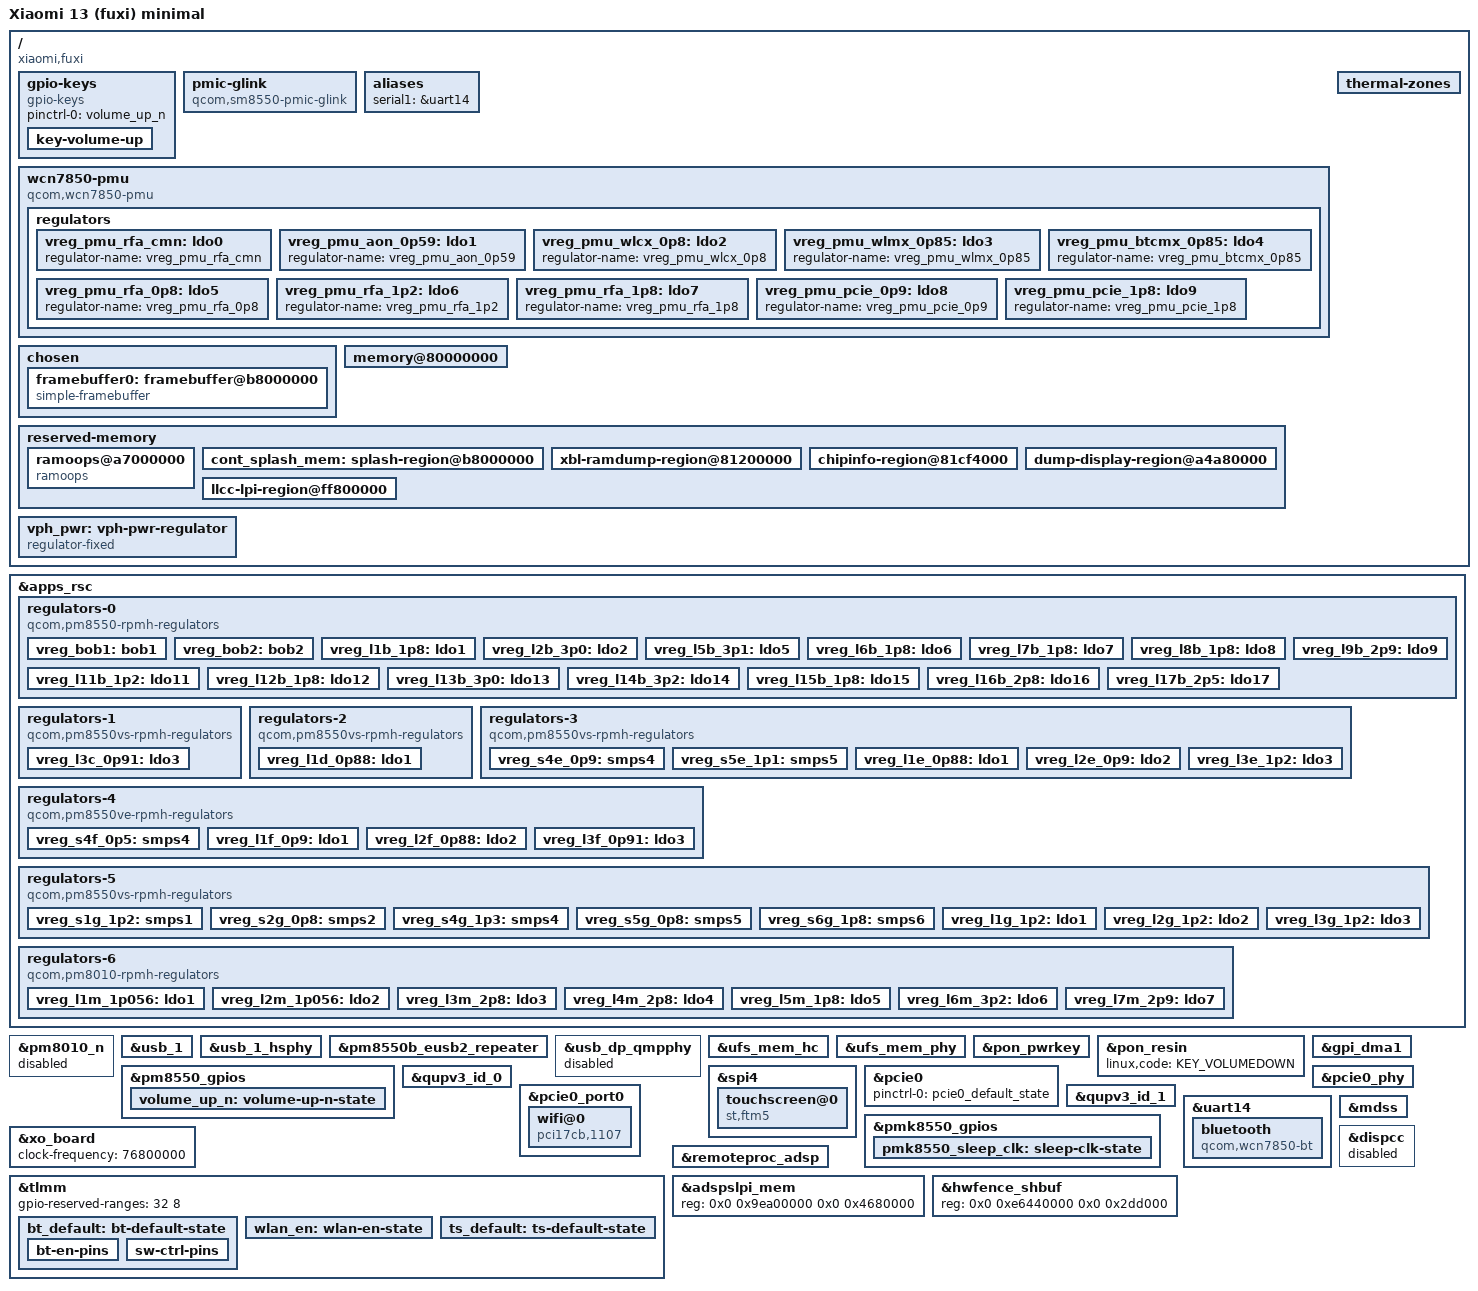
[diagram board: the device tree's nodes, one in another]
// SPDX-License-Identifier: BSD-3-Clause
/*
 * Xiaomi 13 (fuxi) 最小主线板级 DTS —— 只为“内核能启动 + USB 串口工作”
 * 生成方式：从 sm8550-mtp.dts 裁剪（保留 PMIC 调压器与 USB 子树）
 */

/dts-v1/;

#include <dt-bindings/regulator/qcom,rpmh-regulator.h>
#include "sm8550.dtsi"
#include "pm8010.dtsi"
#include "pm8550.dtsi"
#include "pm8550b.dtsi"
#define PMK8550VE_SID 5
#include "pm8550ve.dtsi"
#include "pm8550vs.dtsi"
#include "pmk8550.dtsi"
#include "pmr735d_a.dtsi"


/ {
	model = "Xiaomi 13 (fuxi) minimal";
	compatible = "xiaomi,fuxi", "qcom,sm8550";
	chassis-type = "handset";

	/* ABL 按这两项从 boot 镜像里挑 DTB（值取自厂商 fuxi DTB）；没有它们 ABL 报 Load Error */
	qcom,msm-id = <519 0x20000>, <536 0x20000>;
	qcom,board-id = <0x10008 0>;

	/* 音量上：PM8550 GPIO6，低有效（厂商 DTB gpio_keys/vol_up；与 sm8550-qrd 相同） */
	gpio-keys {
		compatible = "gpio-keys";

		pinctrl-0 = <&volume_up_n>;
		pinctrl-names = "default";

		key-volume-up {
			label = "Volume Up";
			linux,code = <KEY_VOLUMEUP>;
			gpios = <&pm8550_gpios 6 GPIO_ACTIVE_LOW>;
			debounce-interval = <15>;
			linux,can-disable;
			wakeup-source;
		};
	};

	/*
	 * 电池/充电：ADSP 上的 battmgr 经 pmic_glink 暴露电量与充电状态。
	 * 暂不接 USB-C connector（不编 UCSI），USB 保持固定 peripheral，免得 ADSP 切换角色断开 USB 网络。
	 */
	pmic-glink {
		compatible = "qcom,sm8550-pmic-glink", "qcom,pmic-glink";
		#address-cells = <1>;
		#size-cells = <0>;
	};

	aliases {
		serial1 = &uart14;
	};

	/*
	 * WiFi/蓝牙：WCN7850（Kiwi）。引脚与 sm8550-qrd 完全相同（厂商 DTB cnss/bt_kiwi：
	 * wlan-en GPIO80、bt-en GPIO81、sw-ctrl GPIO82；PCIe0 perst GPIO94、wake GPIO96），
	 * 供电对应关系同 QRD（只是 fuxi DTS 里的标签名不同）。
	 */
	wcn7850-pmu {
		compatible = "qcom,wcn7850-pmu";

		pinctrl-0 = <&wlan_en>, <&bt_default>, <&pmk8550_sleep_clk>;
		pinctrl-names = "default";

		wlan-enable-gpios = <&tlmm 80 GPIO_ACTIVE_HIGH>;
		bt-enable-gpios = <&tlmm 81 GPIO_ACTIVE_HIGH>;

		vdd-supply = <&vreg_s5g_0p8>;
		vddio-supply = <&vreg_l15b_1p8>;
		vddaon-supply = <&vreg_s2g_0p8>;
		vdddig-supply = <&vreg_s4e_0p9>;
		vddrfa1p2-supply = <&vreg_s4g_1p3>;
		vddrfa1p8-supply = <&vreg_s6g_1p8>;

		regulators {
			vreg_pmu_rfa_cmn: ldo0 {
				regulator-name = "vreg_pmu_rfa_cmn";
			};

			vreg_pmu_aon_0p59: ldo1 {
				regulator-name = "vreg_pmu_aon_0p59";
			};

			vreg_pmu_wlcx_0p8: ldo2 {
				regulator-name = "vreg_pmu_wlcx_0p8";
			};

			vreg_pmu_wlmx_0p85: ldo3 {
				regulator-name = "vreg_pmu_wlmx_0p85";
			};

			vreg_pmu_btcmx_0p85: ldo4 {
				regulator-name = "vreg_pmu_btcmx_0p85";
			};

			vreg_pmu_rfa_0p8: ldo5 {
				regulator-name = "vreg_pmu_rfa_0p8";
			};

			vreg_pmu_rfa_1p2: ldo6 {
				regulator-name = "vreg_pmu_rfa_1p2";
			};

			vreg_pmu_rfa_1p8: ldo7 {
				regulator-name = "vreg_pmu_rfa_1p8";
			};

			vreg_pmu_pcie_0p9: ldo8 {
				regulator-name = "vreg_pmu_pcie_0p9";
			};

			vreg_pmu_pcie_1p8: ldo9 {
				regulator-name = "vreg_pmu_pcie_1p8";
			};
		};
	};

	chosen {
		#address-cells = <2>;
		#size-cells = <2>;
		ranges;

		/*
		 * 内核 cmdline 的唯一来源（ABL 启动时内核用内建 DTB，ABL 传的 cmdline 不生效）。
		 * 末尾的空格是给旧的 UEFI 跳板（FuxiLinuxBoot 原地改写）留的余量。
		 * 不要加 console=ttyGS0：/dev/console 会变成 USB 串口，主机没打开串口时缓冲区写满，
		 * 往 /dev/console 写的进程（systemd 状态输出）全部阻塞——启动卡 6 分钟、关机永远卡住。
		 */
		bootargs = "loglevel=7 log_buf_len=2M panic=0 clk_ignore_unused pd_ignore_unused regulator_ignore_unused arm-smmu.disable_bypass=0 cpuidle.off=1 fbcon=font:TER16x32 console=tty0 fuxi.fb=0xB8000000,1080,2400,1080,32 rdinit=/init g_cdc.idVendor=0x0525 g_cdc.idProduct=0xa4a7 g_cdc.dev_addr=02:f0:c5:13:00:02 g_cdc.host_addr=02:f0:c5:13:00:01                                                                                                                                                                                                                                                                                                                                                                                                                                                                                                                                                                                                                                                                                                                                                                                                                                ";

		/*
		 * bootloader（ABL/UEFI）留下的帧缓冲：1080x2400 XRGB8888，stride 4320。
		 * 面板是 DSI command mode，MDSS autorefresh 持续从这里取帧；simpledrm 接管它
		 * 当作标准显示设备（/dev/dri/card0 + fbcon）。内存在 reserved-memory 里保留。
		 */
		framebuffer0: framebuffer@b8000000 {
			compatible = "simple-framebuffer";
			reg = <0x0 0xb8000000 0x0 0x9e3400>;
			width = <1080>;
			height = <2400>;
			stride = <(1080 * 4)>;
			format = "x8r8g8b8";
		};
	};

	/*
	 * 内存与固件保留区按"运行中系统"的 DTB（/sys/firmware/fdt，ABL 按本机 DDR 改写过，
	 * 存档 work/device-info/fuxi-live.dts）：这台是 12 GB 版本。之前这里的布局来自不匹配的
	 * 厂商 DTB：少了 4 GB，还把 0x8b9d00000 等几段非内存/受保护区声明成了内存。
	 * 内建 DTB 忽略 ABL 的改写，所以这份布局只对这台机器有效。
	 */
	memory@80000000 {
		device_type = "memory";
		reg = <0x0 0x80000000 0x0 0x00e00000>,
		      <0x0 0x811d0000 0x0 0x56e30000>,
		      <0x0 0xd8140000 0x0 0x00020000>,
		      <0x0 0xe7cb0000 0x0 0x18350000>,
		      <0x8 0x80000000 0x0 0x39d00000>,
		      <0x8 0xb9f00000 0x0 0x01e00000>,
		      <0x8 0xc0000000 0x0 0xc0000000>,
		      <0x9 0x80000000 0x1 0x80000000>;
	};

	/*
	 * 固件保留区以 sm8550.dtsi 为准（与本机固件布局一致），只补运行中 DTB 里多出来的几段，
	 * 尺寸不同的在文件末尾按标签改。
	 */
	reserved-memory {
		#address-cells = <2>;
		#size-cells = <2>;
		ranges;

		/*
		 * 厂商 DTB 的 ramoops@0xa7000000：热重启后保留上一轮的内核日志（/sys/fs/pstore），
		 * 用来查卡死/重启原因。4 MB = 2 MB console + 2 MB pmsg，与 Android 一致。
		 */
		ramoops@a7000000 {
			compatible = "ramoops";
			reg = <0x0 0xa7000000 0x0 0x400000>;
			console-size = <0x200000>;
			pmsg-size = <0x200000>;
		};

		/* 厂商 DTB 的 cont_splash_region：bootloader 帧缓冲，不能给内核当普通内存用 */
		cont_splash_mem: splash-region@b8000000 {
			reg = <0x0 0xb8000000 0x0 0x2b00000>;
			no-map;
		};

		xbl-ramdump-region@81200000 {
			reg = <0x0 0x81200000 0x0 0x280000>;
			no-map;
		};

		chipinfo-region@81cf4000 {
			reg = <0x0 0x81cf4000 0x0 0x1000>;
			no-map;
		};

		dump-display-region@a4a80000 {
			reg = <0x0 0xa4a80000 0x0 0x800>;
			no-map;
		};

		llcc-lpi-region@ff800000 {
			reg = <0x0 0xff800000 0x0 0x600000>;
			no-map;
		};
	};

	vph_pwr: vph-pwr-regulator {
		compatible = "regulator-fixed";
		regulator-name = "vph_pwr";
		regulator-min-microvolt = <3700000>;
		regulator-max-microvolt = <3700000>;
		regulator-always-on;
		regulator-boot-on;
	};
};

&apps_rsc {
	regulators-0 {
		compatible = "qcom,pm8550-rpmh-regulators";
		qcom,pmic-id = "b";

		vdd-bob1-supply = <&vph_pwr>;
		vdd-bob2-supply = <&vph_pwr>;
		vdd-l1-l4-l10-supply = <&vreg_s6g_1p8>;
		vdd-l2-l13-l14-supply = <&vreg_bob1>;
		vdd-l3-supply = <&vreg_s4g_1p3>;
		vdd-l5-l16-supply = <&vreg_bob1>;
		vdd-l6-l7-supply = <&vreg_bob1>;
		vdd-l8-l9-supply = <&vreg_bob1>;
		vdd-l11-supply = <&vreg_s4g_1p3>;
		vdd-l12-supply = <&vreg_s6g_1p8>;
		vdd-l15-supply = <&vreg_s6g_1p8>;
		vdd-l17-supply = <&vreg_bob2>;

		vreg_bob1: bob1 {
			regulator-name = "vreg_bob1";
			regulator-min-microvolt = <3296000>;
			regulator-max-microvolt = <3960000>;
			regulator-initial-mode = <RPMH_REGULATOR_MODE_HPM>;
		};

		vreg_bob2: bob2 {
			regulator-name = "vreg_bob2";
			regulator-min-microvolt = <2720000>;
			regulator-max-microvolt = <3960000>;
			regulator-initial-mode = <RPMH_REGULATOR_MODE_HPM>;
		};

		vreg_l1b_1p8: ldo1 {
			regulator-name = "vreg_l1b_1p8";
			regulator-min-microvolt = <1800000>;
			regulator-max-microvolt = <1800000>;
			regulator-initial-mode = <RPMH_REGULATOR_MODE_HPM>;
		};

		vreg_l2b_3p0: ldo2 {
			regulator-name = "vreg_l2b_3p0";
			regulator-min-microvolt = <3008000>;
			regulator-max-microvolt = <3008000>;
			regulator-initial-mode = <RPMH_REGULATOR_MODE_HPM>;
		};

		vreg_l5b_3p1: ldo5 {
			regulator-name = "vreg_l5b_3p1";
			regulator-min-microvolt = <3104000>;
			regulator-max-microvolt = <3104000>;
			regulator-initial-mode = <RPMH_REGULATOR_MODE_HPM>;
		};

		vreg_l6b_1p8: ldo6 {
			regulator-name = "vreg_l6b_1p8";
			regulator-min-microvolt = <1800000>;
			regulator-max-microvolt = <3008000>;
			regulator-initial-mode = <RPMH_REGULATOR_MODE_HPM>;
		};

		vreg_l7b_1p8: ldo7 {
			regulator-name = "vreg_l7b_1p8";
			regulator-min-microvolt = <1800000>;
			regulator-max-microvolt = <3008000>;
			regulator-initial-mode = <RPMH_REGULATOR_MODE_HPM>;
		};

		vreg_l8b_1p8: ldo8 {
			regulator-name = "vreg_l8b_1p8";
			regulator-min-microvolt = <1800000>;
			regulator-max-microvolt = <3008000>;
			regulator-initial-mode = <RPMH_REGULATOR_MODE_HPM>;
		};

		vreg_l9b_2p9: ldo9 {
			regulator-name = "vreg_l9b_2p9";
			regulator-min-microvolt = <2960000>;
			regulator-max-microvolt = <3008000>;
			regulator-initial-mode = <RPMH_REGULATOR_MODE_HPM>;
		};

		vreg_l11b_1p2: ldo11 {
			regulator-name = "vreg_l11b_1p2";
			regulator-min-microvolt = <1200000>;
			regulator-max-microvolt = <1504000>;
			regulator-initial-mode = <RPMH_REGULATOR_MODE_HPM>;
		};

		vreg_l12b_1p8: ldo12 {
			regulator-name = "vreg_l12b_1p8";
			regulator-min-microvolt = <1800000>;
			regulator-max-microvolt = <1800000>;
			regulator-initial-mode = <RPMH_REGULATOR_MODE_HPM>;
		};

		vreg_l13b_3p0: ldo13 {
			regulator-name = "vreg_l13b_3p0";
			regulator-min-microvolt = <3000000>;
			regulator-max-microvolt = <3000000>;
			regulator-initial-mode = <RPMH_REGULATOR_MODE_HPM>;
		};

		vreg_l14b_3p2: ldo14 {
			regulator-name = "vreg_l14b_3p2";
			regulator-min-microvolt = <3200000>;
			regulator-max-microvolt = <3200000>;
			regulator-initial-mode = <RPMH_REGULATOR_MODE_HPM>;
		};

		vreg_l15b_1p8: ldo15 {
			regulator-name = "vreg_l15b_1p8";
			regulator-min-microvolt = <1800000>;
			regulator-max-microvolt = <1800000>;
			regulator-initial-mode = <RPMH_REGULATOR_MODE_HPM>;
		};

		vreg_l16b_2p8: ldo16 {
			regulator-name = "vreg_l16b_2p8";
			regulator-min-microvolt = <2800000>;
			regulator-max-microvolt = <2800000>;
			regulator-initial-mode = <RPMH_REGULATOR_MODE_HPM>;
		};

		vreg_l17b_2p5: ldo17 {
			regulator-name = "vreg_l17b_2p5";
			regulator-min-microvolt = <2504000>;
			regulator-max-microvolt = <2504000>;
			regulator-initial-mode = <RPMH_REGULATOR_MODE_HPM>;
		};
	};

	regulators-1 {
		compatible = "qcom,pm8550vs-rpmh-regulators";
		qcom,pmic-id = "c";

		vdd-l3-supply = <&vreg_s4e_0p9>;

		vreg_l3c_0p91: ldo3 {
			regulator-name = "vreg_l3c_0p9";
			regulator-min-microvolt = <880000>;
			regulator-max-microvolt = <912000>;
			regulator-initial-mode = <RPMH_REGULATOR_MODE_HPM>;
		};
	};

	regulators-2 {
		compatible = "qcom,pm8550vs-rpmh-regulators";
		qcom,pmic-id = "d";

		vdd-l1-supply = <&vreg_s4e_0p9>;

		vreg_l1d_0p88: ldo1 {
			regulator-name = "vreg_l1d_0p88";
			regulator-min-microvolt = <880000>;
			regulator-max-microvolt = <920000>;
			regulator-initial-mode = <RPMH_REGULATOR_MODE_HPM>;
		};
	};

	regulators-3 {
		compatible = "qcom,pm8550vs-rpmh-regulators";
		qcom,pmic-id = "e";

		vdd-l1-supply = <&vreg_s4e_0p9>;
		vdd-l2-supply = <&vreg_s4e_0p9>;
		vdd-l3-supply = <&vreg_s4g_1p3>;
		vdd-s4-supply = <&vph_pwr>;
		vdd-s5-supply = <&vph_pwr>;

		vreg_s4e_0p9: smps4 {
			regulator-name = "vreg_s4e_0p9";
			regulator-min-microvolt = <904000>;
			regulator-max-microvolt = <984000>;
			regulator-initial-mode = <RPMH_REGULATOR_MODE_HPM>;
		};

		vreg_s5e_1p1: smps5 {
			regulator-name = "vreg_s5e_1p1";
			regulator-min-microvolt = <1080000>;
			regulator-max-microvolt = <1120000>;
			regulator-initial-mode = <RPMH_REGULATOR_MODE_HPM>;
		};

		vreg_l1e_0p88: ldo1 {
			regulator-name = "vreg_l1e_0p88";
			regulator-min-microvolt = <880000>;
			regulator-max-microvolt = <880000>;
			regulator-initial-mode = <RPMH_REGULATOR_MODE_HPM>;
		};

		vreg_l2e_0p9: ldo2 {
			regulator-name = "vreg_l2e_0p9";
			regulator-min-microvolt = <904000>;
			regulator-max-microvolt = <970000>;
			regulator-initial-mode = <RPMH_REGULATOR_MODE_HPM>;
		};

		vreg_l3e_1p2: ldo3 {
			regulator-name = "vreg_l3e_1p2";
			regulator-min-microvolt = <1200000>;
			regulator-max-microvolt = <1200000>;
			regulator-initial-mode = <RPMH_REGULATOR_MODE_HPM>;
		};
	};

	regulators-4 {
		compatible = "qcom,pm8550ve-rpmh-regulators";
		qcom,pmic-id = "f";

		vdd-l1-supply = <&vreg_s4e_0p9>;
		vdd-l2-supply = <&vreg_s4e_0p9>;
		vdd-l3-supply = <&vreg_s4e_0p9>;
		vdd-s4-supply = <&vph_pwr>;

		vreg_s4f_0p5: smps4 {
			regulator-name = "vreg_s4f_0p5";
			regulator-min-microvolt = <500000>;
			regulator-max-microvolt = <700000>;
			regulator-initial-mode = <RPMH_REGULATOR_MODE_HPM>;
		};

		vreg_l1f_0p9: ldo1 {
			regulator-name = "vreg_l1f_0p9";
			regulator-min-microvolt = <912000>;
			regulator-max-microvolt = <912000>;
			regulator-initial-mode = <RPMH_REGULATOR_MODE_HPM>;
		};

		vreg_l2f_0p88: ldo2 {
			regulator-name = "vreg_l2f_0p88";
			regulator-min-microvolt = <880000>;
			regulator-max-microvolt = <912000>;
			regulator-initial-mode = <RPMH_REGULATOR_MODE_HPM>;
		};

		vreg_l3f_0p91: ldo3 {
			regulator-name = "vreg_l3f_0p91";
			regulator-min-microvolt = <880000>;
			regulator-max-microvolt = <912000>;
			regulator-initial-mode = <RPMH_REGULATOR_MODE_HPM>;
		};
	};

	regulators-5 {
		compatible = "qcom,pm8550vs-rpmh-regulators";
		qcom,pmic-id = "g";

		vdd-l1-supply = <&vreg_s4g_1p3>;
		vdd-l2-supply = <&vreg_s4g_1p3>;
		vdd-l3-supply = <&vreg_s4g_1p3>;
		vdd-s1-supply = <&vph_pwr>;
		vdd-s2-supply = <&vph_pwr>;
		vdd-s3-supply = <&vph_pwr>;
		vdd-s4-supply = <&vph_pwr>;
		vdd-s5-supply = <&vph_pwr>;
		vdd-s6-supply = <&vph_pwr>;

		vreg_s1g_1p2: smps1 {
			regulator-name = "vreg_s1g_1p2";
			regulator-min-microvolt = <1200000>;
			regulator-max-microvolt = <1300000>;
			regulator-initial-mode = <RPMH_REGULATOR_MODE_HPM>;
		};

		vreg_s2g_0p8: smps2 {
			regulator-name = "vreg_s2g_0p8";
			regulator-min-microvolt = <800000>;
			regulator-max-microvolt = <1000000>;
			regulator-initial-mode = <RPMH_REGULATOR_MODE_HPM>;
		};

		/*
		 * fuxi 的 cmd-db 没有 smpg3（work/device-info/cmd-db-fuxi.txt），
		 * 保留 MTP 的 smps3 会让整块 regulators-5 以 -ENODEV 静默失败。
		 */

		vreg_s4g_1p3: smps4 {
			regulator-name = "vreg_s4g_1p3";
			regulator-min-microvolt = <1200000>;
			regulator-max-microvolt = <1352000>;
			regulator-initial-mode = <RPMH_REGULATOR_MODE_HPM>;
		};

		vreg_s5g_0p8: smps5 {
			regulator-name = "vreg_s5g_0p8";
			regulator-min-microvolt = <500000>;
			regulator-max-microvolt = <1004000>;
			regulator-initial-mode = <RPMH_REGULATOR_MODE_HPM>;
		};

		vreg_s6g_1p8: smps6 {
			regulator-name = "vreg_s6g_1p8";
			regulator-min-microvolt = <1800000>;
			regulator-max-microvolt = <2000000>;
			regulator-initial-mode = <RPMH_REGULATOR_MODE_HPM>;
		};

		vreg_l1g_1p2: ldo1 {
			regulator-name = "vreg_l1g_1p2";
			regulator-min-microvolt = <1200000>;
			regulator-max-microvolt = <1200000>;
			regulator-initial-mode = <RPMH_REGULATOR_MODE_HPM>;
		};

		vreg_l2g_1p2: ldo2 {
			regulator-name = "vreg_l2g_1p2";
			regulator-min-microvolt = <1200000>;
			regulator-max-microvolt = <1200000>;
			regulator-initial-mode = <RPMH_REGULATOR_MODE_HPM>;
		};

		vreg_l3g_1p2: ldo3 {
			regulator-name = "vreg_l3g_1p2";
			regulator-min-microvolt = <1200000>;
			regulator-max-microvolt = <1200000>;
			regulator-initial-mode = <RPMH_REGULATOR_MODE_HPM>;
		};
	};

	regulators-6 {
		compatible = "qcom,pm8010-rpmh-regulators";
		qcom,pmic-id = "m";

		vdd-l1-l2-supply = <&vreg_s4g_1p3>;
		vdd-l3-l4-supply = <&vreg_bob2>;
		vdd-l5-supply = <&vreg_s6g_1p8>;
		vdd-l6-supply = <&vreg_s6g_1p8>;
		vdd-l7-supply = <&vreg_bob1>;

		vreg_l1m_1p056: ldo1 {
			regulator-name = "vreg_l1m_1p056";
			regulator-min-microvolt = <1056000>;
			regulator-max-microvolt = <1056000>;
			regulator-initial-mode = <RPMH_REGULATOR_MODE_HPM>;
		};

		vreg_l2m_1p056: ldo2 {
			regulator-name = "vreg_l2m_1p056";
			regulator-min-microvolt = <1056000>;
			regulator-max-microvolt = <1056000>;
			regulator-initial-mode = <RPMH_REGULATOR_MODE_HPM>;
		};

		vreg_l3m_2p8: ldo3 {
			regulator-name = "vreg_l3m_2p8";
			regulator-min-microvolt = <2800000>;
			regulator-max-microvolt = <2800000>;
			regulator-initial-mode = <RPMH_REGULATOR_MODE_HPM>;
		};

		vreg_l4m_2p8: ldo4 {
			regulator-name = "vreg_l4m_2p8";
			regulator-min-microvolt = <2800000>;
			regulator-max-microvolt = <2800000>;
			regulator-initial-mode = <RPMH_REGULATOR_MODE_HPM>;
		};

		vreg_l5m_1p8: ldo5 {
			regulator-name = "vreg_l5m_1p8";
			regulator-min-microvolt = <1800000>;
			regulator-max-microvolt = <1800000>;
			regulator-initial-mode = <RPMH_REGULATOR_MODE_HPM>;
		};

		/* 只给触摸屏 avdd 用；厂商 pm8010m_l6 默认 3.2V（范围 1.8–3.2V） */
		vreg_l6m_3p2: ldo6 {
			regulator-name = "vreg_l6m_3p2";
			regulator-min-microvolt = <3200000>;
			regulator-max-microvolt = <3200000>;
			regulator-initial-mode = <RPMH_REGULATOR_MODE_HPM>;
		};

		vreg_l7m_2p9: ldo7 {
			regulator-name = "vreg_l7m_2p9";
			regulator-min-microvolt = <2800000>;
			regulator-max-microvolt = <2904000>;
			regulator-initial-mode = <RPMH_REGULATOR_MODE_HPM>;
		};
	};

	/* PMIC "n"（第二颗 PM8010）在 fuxi 的 cmd-db 里没有任何资源：去掉 regulators-7 */
};

/*
 * fuxi 只有一颗 PM8010（USID 0xc）、一颗 PMR735D（0xa）：0xb/0xd 不存在（cmd-db 里也没有
 * PMIC "n" 的资源），probe 会报 spmi 通道错误并打调用栈。pmr735d_b.dtsi 不包含；pm8010.dtsi
 * 里的第二颗关掉，连同它的温度区。
 */
&pm8010_n {
	status = "disabled";
};

/ {
	thermal-zones {
		/delete-node/ pm8010-n-thermal;
	};
};

/* ===== USB：只要 gadget 串口能用（仅 USB2/eUSB2，不碰 USB3/DP combo PHY）===== */
&usb_1 {
	dr_mode = "peripheral";
	/delete-property/ usb-role-switch;
	phys = <&usb_1_hsphy>;
	phy-names = "usb2-phy";
	maximum-speed = "high-speed";
	/* 没有 SS PHY 提供 pipe clock，改用 UTMI 时钟 */
	qcom,select-utmi-as-pipe-clk;
	status = "okay";
};

&usb_1_hsphy {
	vdd-supply = <&vreg_l1e_0p88>;
	vdda12-supply = <&vreg_l3e_1p2>;

	phys = <&pm8550b_eusb2_repeater>;

	status = "okay";
};

/* repeater 在 PM8550B 上（SPMI 总线），供电同 sm8550-qrd */
&pm8550b_eusb2_repeater {
	vdd18-supply = <&vreg_l15b_1p8>;
	vdd3-supply = <&vreg_l5b_3p1>;
};

&usb_dp_qmpphy {
	vdda-phy-supply = <&vreg_l3f_0p91>;
	vdda-pll-supply = <&vreg_l3e_1p2>;

	status = "disabled";
};

/*
 * ===== UFS（M3）=====
 * 与 Android 实时 DTB（work/device-info/fuxi-live.dts，ufshc@1d84000）逐项核对过：
 * vcc=pm_humu_l17(l17b 2.504V)/1.3A、vccq=pm_v6g_l1(l1g)/1.2A、reset GPIO 210；
 * PHY vdda-phy=l1d、vdda-pll=l3e。与 sm8550-mtp 相同。
 */
&ufs_mem_hc {
	reset-gpios = <&tlmm 210 GPIO_ACTIVE_LOW>;
	vcc-supply = <&vreg_l17b_2p5>;
	vcc-max-microamp = <1300000>;
	vccq-supply = <&vreg_l1g_1p2>;
	vccq-max-microamp = <1200000>;
	vdd-hba-supply = <&vreg_l3g_1p2>;

	status = "okay";
};

&ufs_mem_phy {
	vdda-phy-supply = <&vreg_l1d_0p88>;
	vdda-pll-supply = <&vreg_l3e_1p2>;

	status = "okay";
};

/* 电源键与音量下（PMK8550 PON 的 resin），同 sm8550-qrd */
&pon_pwrkey {
	status = "okay";
};

&pon_resin {
	linux,code = <KEY_VOLUMEDOWN>;

	status = "okay";
};

&pm8550_gpios {
	volume_up_n: volume-up-n-state {
		pins = "gpio6";
		function = "normal";
		power-source = <1>;
		bias-pull-up;
		input-enable;
	};
};

/*
 * 触摸屏：ST FTM5（SPI，QUP0 SE4 = spi4，GPIO44-47），驱动 drivers/input/touchscreen/st-ftm5.c。
 * 取自厂商 DTB spi@a90000/fts@0："st,spi"、12 MHz、irq GPIO25 低电平、reset GPIO24（拉低复位）、
 * vdd = l12b（pm_humu_l12）、avdd = l6m（pm8010m_l6）。坐标是 1/10 像素（1080x2400 屏）。
 */
&gpi_dma1 {
	status = "okay";
};

&qupv3_id_0 {
	status = "okay";
};

&spi4 {
	status = "okay";

	touchscreen@0 {
		compatible = "st,ftm5";
		reg = <0>;
		spi-max-frequency = <12000000>;

		interrupts-extended = <&tlmm 25 IRQ_TYPE_LEVEL_LOW>;
		reset-gpios = <&tlmm 24 GPIO_ACTIVE_LOW>;

		vdd-supply = <&vreg_l12b_1p8>;
		avdd-supply = <&vreg_l6m_3p2>;

		pinctrl-0 = <&ts_default>;
		pinctrl-names = "default";

		touchscreen-size-x = <10800>;
		touchscreen-size-y = <24000>;
	};
};

&pcie0 {
	pinctrl-0 = <&pcie0_default_state>;
	pinctrl-names = "default";

	status = "okay";
};

&pcie0_phy {
	vdda-phy-supply = <&vreg_l1e_0p88>;
	vdda-pll-supply = <&vreg_l3e_1p2>;

	status = "okay";
};

&pcie0_port0 {
	reset-gpios = <&tlmm 94 GPIO_ACTIVE_LOW>;
	wake-gpios = <&tlmm 96 GPIO_ACTIVE_LOW>;

	wifi@0 {
		compatible = "pci17cb,1107";
		reg = <0x10000 0x0 0x0 0x0 0x0>;

		vddrfacmn-supply = <&vreg_pmu_rfa_cmn>;
		vddaon-supply = <&vreg_pmu_aon_0p59>;
		vddwlcx-supply = <&vreg_pmu_wlcx_0p8>;
		vddwlmx-supply = <&vreg_pmu_wlmx_0p85>;
		vddrfa0p8-supply = <&vreg_pmu_rfa_0p8>;
		vddrfa1p2-supply = <&vreg_pmu_rfa_1p2>;
		vddrfa1p8-supply = <&vreg_pmu_rfa_1p8>;
		vddpcie0p9-supply = <&vreg_pmu_pcie_0p9>;
		vddpcie1p8-supply = <&vreg_pmu_pcie_1p8>;
	};
};

/* QUP2（0x8c0000，主线叫 qupv3_id_1）：uart14 蓝牙、i2c8 扬声器功放都在它下面 */
&qupv3_id_1 {
	status = "okay";
};

&uart14 {
	status = "okay";

	bluetooth {
		compatible = "qcom,wcn7850-bt";

		vddrfacmn-supply = <&vreg_pmu_rfa_cmn>;
		vddaon-supply = <&vreg_pmu_aon_0p59>;
		vddwlcx-supply = <&vreg_pmu_wlcx_0p8>;
		vddwlmx-supply = <&vreg_pmu_wlmx_0p85>;
		vddrfa0p8-supply = <&vreg_pmu_rfa_0p8>;
		vddrfa1p2-supply = <&vreg_pmu_rfa_1p2>;
		vddrfa1p8-supply = <&vreg_pmu_rfa_1p8>;

		max-speed = <3200000>;
	};
};

&pmk8550_gpios {
	pmk8550_sleep_clk: sleep-clk-state {
		pins = "gpio3";
		function = "func1";
		input-disable;
		output-enable;
		bias-disable;
		power-source = <0>;
	};
};

&xo_board {
	clock-frequency = <76800000>;
};

/*
 * GPIO 32-39 归 TrustZone（厂商 kalama DTB: qcom,gpios-reserved = <32..39>）。
 * 缺这一行时 TLMM probe 读这些引脚的寄存器触发 XPU 违规：黑屏 + 整机卡死 + 看门狗复位。
 */
&tlmm {
	gpio-reserved-ranges = <32 8>;

	bt_default: bt-default-state {
		bt-en-pins {
			pins = "gpio81";
			function = "gpio";
			drive-strength = <16>;
			bias-disable;
		};

		sw-ctrl-pins {
			pins = "gpio82";
			function = "gpio";
			bias-pull-down;
		};
	};

	wlan_en: wlan-en-state {
		pins = "gpio80";
		function = "gpio";
		drive-strength = <8>;
		bias-pull-down;
	};

	/* 厂商 mi_ts_active：GPIO24（reset）、GPIO25（irq），上拉、8 mA */
	ts_default: ts-default-state {
		pins = "gpio24", "gpio25";
		function = "gpio";
		drive-strength = <8>;
		bias-pull-up;
	};
};

/*
 * 显示：暂时只用 simpledrm 接管 bootloader 点亮的帧缓冲（chosen/framebuffer）。
 * MDSS 节点打开但不编 DRM_MSM：它作为"永远等不到驱动"的消费者，让 fw_devlink 把
 * mmss_noc/gem_noc 带宽和 MMCX（mdp 子节点的 power-domain）的 sync_state 一直挂起，
 * bootloader 的投票得以保留；否则这些 provider sync_state 后投票归零，画面冻结。
 * 以后接入 DRM_MSM + 面板驱动时直接接管。dispcc 保持关闭，免得它的驱动动显示时钟。
 *
 * 去掉 iommus：节点一启用，MDSS 就被挂进 SMMU 的 DMA 域（地址翻译），没人给帧缓冲建映射，
 * 显示控制器（stream 0x1c00）读 0xb8xxxxxx 全部 context fault → 黑屏。不挂 SMMU 时这个
 * stream 走 bypass，直接读物理内存。接入 DRM_MSM 时恢复。
 */
&mdss {
	/delete-property/ iommus;
	status = "okay";
};

&dispcc {
	status = "disabled";
};

/*
 * ADSP：固件从 Android 的 /vendor/firmware_mnt/image 复制（adsp.mdt + .bNN、adsp_dtb.mdt + .bNN），
 * 放在 Ubuntu 的 /lib/firmware/qcom/sm8550/xiaomi/fuxi/。initramfs 阶段 probe 时找不到固件，
 * 由 Ubuntu 里的 fuxi-remoteproc.service 在根文件系统挂好后启动。
 */
&remoteproc_adsp {
	firmware-name = "qcom/sm8550/xiaomi/fuxi/adsp.mdt",
			"qcom/sm8550/xiaomi/fuxi/adsp_dtb.mdt";
	status = "okay";
};

/* 运行中 DTB 里比 sm8550.dtsi 大的两段（Xiaomi 固件更大） */
&adspslpi_mem {
	reg = <0x0 0x9ea00000 0x0 0x4680000>;
};

&hwfence_shbuf {
	reg = <0x0 0xe6440000 0x0 0x2dd000>;
};
